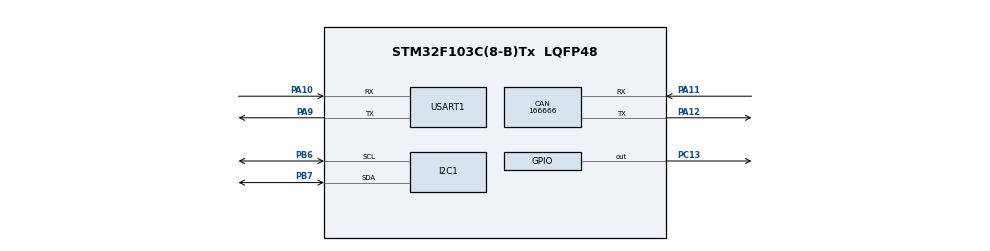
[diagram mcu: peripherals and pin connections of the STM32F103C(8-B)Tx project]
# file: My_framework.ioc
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CAN.CalculateBaudRate=166666
CAN.CalculateTimeBit=6000
CAN.CalculateTimeQuantum=2000.0
Dma.Request0=USART1_RX
Dma.USART1_RX.0.Direction=DMA_PERIPH_TO_MEMORY
Dma.USART1_RX.0.Instance=DMA1_Channel5
Dma.USART1_RX.0.MemDataAlignment=DMA_MDATAALIGN_BYTE
Dma.USART1_RX.0.MemInc=DMA_MINC_ENABLE
Dma.USART1_RX.0.Mode=DMA_NORMAL
Dma.USART1_RX.0.PeriphDataAlignment=DMA_PDATAALIGN_BYTE
Dma.USART1_RX.0.PeriphInc=DMA_PINC_DISABLE
Dma.USART1_RX.0.Priority=DMA_PRIORITY_LOW
FREERTOS.Tasks01=defaultTask,24,512,StartDefaultTask,Default,NULL,Dynamic,NULL,NULL
Mcu.Family=STM32F1
Mcu.Name=STM32F103C(8-B)Tx
Mcu.Package=LQFP48
NVIC.DMA1_Channel5_IRQn=true\:5\:0\:false\:false\:true\:true\:false\:true\:true
NVIC.I2C1_ER_IRQn=true\:5\:0\:false\:false\:true\:true\:true\:true\:true
NVIC.I2C1_EV_IRQn=true\:5\:0\:false\:false\:true\:true\:true\:true\:true
NVIC.PriorityGroup=NVIC_PRIORITYGROUP_4
NVIC.TIM3_IRQn=true\:5\:0\:false\:false\:true\:true\:true\:true\:true
NVIC.USART1_IRQn=true\:5\:0\:false\:false\:true\:true\:true\:true\:true
NVIC.USB_LP_CAN1_RX0_IRQn=true\:5\:0\:false\:false\:true\:true\:true\:true\:true
PA10.Mode=Asynchronous
PA10.Signal=USART1_RX
PA11.Mode=CAN_Activate
PA11.Signal=CAN_RX
PA12.Mode=CAN_Activate
PA12.Signal=CAN_TX
PA13.Mode=Serial_Wire
PA13.Signal=SYS_JTMS-SWDIO
PA14.Mode=Serial_Wire
PA14.Signal=SYS_JTCK-SWCLK
PA9.Mode=Asynchronous
PA9.Signal=USART1_TX
PB6.Mode=I2C
PB6.Signal=I2C1_SCL
PB7.Mode=I2C
PB7.Signal=I2C1_SDA
PC13-TAMPER-RTC.Signal=GPIO_Output
PD0-OSC_IN.Mode=HSE-External-Oscillator
PD0-OSC_IN.Signal=RCC_OSC_IN
PD1-OSC_OUT.Mode=HSE-External-Oscillator
PD1-OSC_OUT.Signal=RCC_OSC_OUT
ProjectManager.HeapSize=0x200
ProjectManager.StackSize=0x400
ProjectManager.TargetToolchain=CMake
RCC.APB1Freq_Value=8000000
RCC.APB2Freq_Value=8000000
USART1.VirtualMode=VM_ASYNC
VP_FREERTOS_VS_CMSIS_V2.Mode=CMSIS_V2
VP_TIM3_VS_ClockSourceINT.Mode=Internal
board=custom

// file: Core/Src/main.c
/* USER CODE BEGIN Header */
/**
  ******************************************************************************
  * @file           : main.c
  * @brief          : Main program body
  ******************************************************************************
  * @attention
  *
  *
  *
  * Copyright (c) 2026 STMicroelectronics.
  * All rights reserved.
  *
  * This software is licensed under terms that can be found in the LICENSE file
  * in the root directory of this software component.
  * If no LICENSE file comes with this software, it is provided AS-IS.
  *
  ******************************************************************************
  */
 //extern void App_Init(void);
/* USER CODE END Header */
#include "main.h"
#include "cmsis_os.h"
#include "can.h"
#include "dma.h"
#include "i2c.h"
#include "tim.h"
#include "usart.h"
#include "gpio.h"

/* USER CODE BEGIN Includes */
extern void App_Init(void);
/* USER CODE END Includes */

void SystemClock_Config(void);
void MX_FREERTOS_Init(void);

int main(void)
{

  /* MCU Configuration--------------------------------------------------------*/

  /* Reset of all peripherals, Initializes the Flash interface and the Systick. */
  HAL_Init();

  /* Configure the system clock */
  SystemClock_Config();

  /* Initialize all configured peripherals */
  MX_GPIO_Init();
  MX_DMA_Init();
  MX_USART1_UART_Init();
  MX_I2C1_Init();
  MX_CAN_Init();
  MX_TIM3_Init();
  /* USER CODE BEGIN 2 */

 // App_Init();
  /* USER CODE END 2 */

  /* Init scheduler */
  osKernelInitialize();  /* Call init function for freertos objects (in cmsis_os2.c) */
  MX_FREERTOS_Init();

  /* Start scheduler */
  osKernelStart();

  /* We should never get here as control is now taken by the scheduler */

  /* Infinite loop */
  while (1)
  {

  }
}

void SystemClock_Config(void)
{
  RCC_OscInitTypeDef RCC_OscInitStruct = {0};
  RCC_ClkInitTypeDef RCC_ClkInitStruct = {0};

  /** Initializes the RCC Oscillators according to the specified parameters
  * in the RCC_OscInitTypeDef structure.
  */
  RCC_OscInitStruct.OscillatorType = RCC_OSCILLATORTYPE_HSI;
  RCC_OscInitStruct.HSIState = RCC_HSI_ON;
  RCC_OscInitStruct.HSICalibrationValue = RCC_HSICALIBRATION_DEFAULT;
  RCC_OscInitStruct.PLL.PLLState = RCC_PLL_NONE;
  if (HAL_RCC_OscConfig(&RCC_OscInitStruct) != HAL_OK)
  {
    Error_Handler();
  }

  /** Initializes the CPU, AHB and APB buses clocks
  */
  RCC_ClkInitStruct.ClockType = RCC_CLOCKTYPE_HCLK|RCC_CLOCKTYPE_SYSCLK
                              |RCC_CLOCKTYPE_PCLK1|RCC_CLOCKTYPE_PCLK2;
  RCC_ClkInitStruct.SYSCLKSource = RCC_SYSCLKSOURCE_HSI;
  RCC_ClkInitStruct.AHBCLKDivider = RCC_SYSCLK_DIV1;
  RCC_ClkInitStruct.APB1CLKDivider = RCC_HCLK_DIV1;
  RCC_ClkInitStruct.APB2CLKDivider = RCC_HCLK_DIV1;

  if (HAL_RCC_ClockConfig(&RCC_ClkInitStruct, FLASH_LATENCY_0) != HAL_OK)
  {
    Error_Handler();
  }
}

/* USER CODE BEGIN 4 */
/* UART 接收回调与 DMA 重新武装已移到 Bsp/Stm32Uart.cpp
   （HAL_UART_RxCpltCallback / HAL_UART_ErrorCallback / UART 空闲中断） */
/* USER CODE END 4 */

void Error_Handler(void)
{
  __disable_irq();
  while (1)
  {
  }
}

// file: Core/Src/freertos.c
/* USER CODE BEGIN Header */
/**
  ******************************************************************************
  * File Name          : freertos.c
  * Description        : Code for freertos applications
  ******************************************************************************
  * @attention
  *
  * Copyright (c) 2026 STMicroelectronics.
  * All rights reserved.
  *
  * This software is licensed under terms that can be found in the LICENSE file
  * in the root directory of this software component.
  * If no LICENSE file comes with this software, it is provided AS-IS.
  *
  ******************************************************************************
  */
/* USER CODE END Header */

#include "FreeRTOS.h"
#include "task.h"
#include "main.h"
#include "cmsis_os.h"

/* USER CODE BEGIN Includes */
extern int App_Init(void);
/* USER CODE END Includes */

/* Definitions for defaultTask */
osThreadId_t defaultTaskHandle;
const osThreadAttr_t defaultTask_attributes = {
  .name = "defaultTask",
  .stack_size = 512 * 4,
  .priority = (osPriority_t) osPriorityNormal,
};

void StartDefaultTask(void *argument);

void MX_FREERTOS_Init(void); /* (MISRA C 2004 rule 8.1) */

void MX_FREERTOS_Init(void) {

  /* Create the thread(s) */
  /* creation of defaultTask */
  defaultTaskHandle = osThreadNew(StartDefaultTask, NULL, &defaultTask_attributes);

}

void StartDefaultTask(void *argument)
{
  /* USER CODE BEGIN StartDefaultTask */
  (void)argument;
  (void)App_Init();      /* 框架初始化；失败原因已在 App_Init 内部打印 */
  vTaskDelete(NULL);     /* 启动任务用完即删，省下 512 字节栈 */
  /* USER CODE END StartDefaultTask */
}
